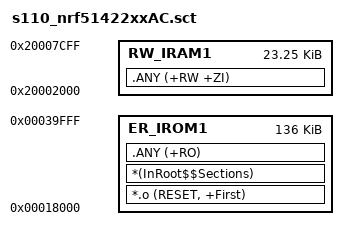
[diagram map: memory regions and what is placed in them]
; ****************************************
; *** Scatter-Loading Description File ***
; ****************************************

; Scatter file for a program IN APPLICATION SPACE, accessing the softdevice
; through SVCs.

LR_IROM1 0x00018000 0x00022000 {  ; Load region size_region
  ER_IROM1 0x00018000 0x00022000 {
   *.o (RESET, +First)
   *(InRoot$$Sections)
   .ANY (+RO)
  }

  RW_IRAM1 0x20002000 0x00005D00 {
   .ANY (+RW +ZI)
  }

  ; Reserve space for the bootloader
  ; CORE_BL_RAM 0x20007D00 0x00002FC {
  ; }
}
